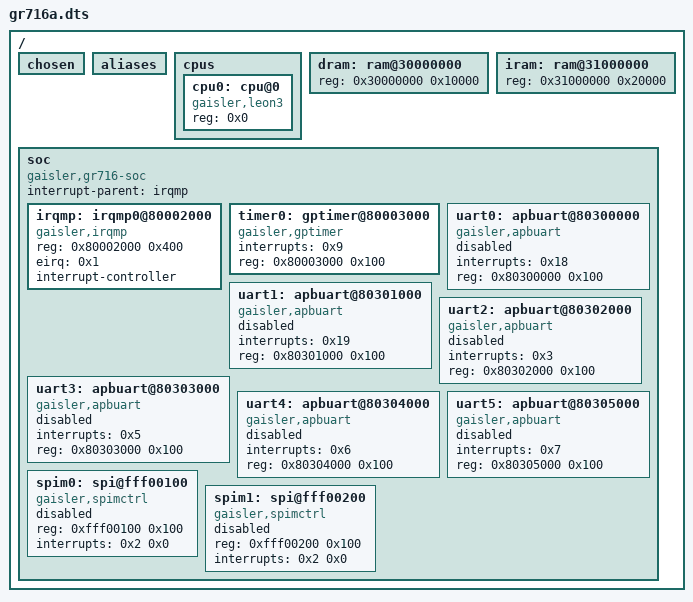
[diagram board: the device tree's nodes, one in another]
/dts-v1/;

/ {
	#address-cells = < 0x1 >;
	#size-cells = < 0x1 >;
	chosen {
	};
	aliases {
	};
	cpus {
		#address-cells = < 0x1 >;
		#size-cells = < 0x0 >;
		cpu0: cpu@0 {
			compatible = "gaisler,leon3";
			reg = < 0x0 >;
		};
	};
	dram: ram@30000000 {
		reg = < 0x30000000 0x10000 >;
	};
	iram: ram@31000000 {
		reg = < 0x31000000 0x20000 >;
	};
	soc {
		#address-cells = < 0x1 >;
		#size-cells = < 0x1 >;
		compatible = "gaisler,gr716-soc", "simple-bus";
		ranges;
		interrupt-parent = < &irqmp >;
		irqmp: irqmp0@80002000 {
			compatible = "gaisler,irqmp";
			reg = < 0x80002000 0x400 >;
			eirq = < 0x1 >;
			interrupt-controller;
			#interrupt-cells = < 0x1 >;
			phandle = < 0x1 >;
		};
		timer0: gptimer@80003000 {
			compatible = "gaisler,gptimer";
			interrupts = < 0x9 >;
			reg = < 0x80003000 0x100 >;
		};
		uart0: apbuart@80300000 {
			compatible = "gaisler,apbuart";
			interrupts = < 0x18 >;
			reg = < 0x80300000 0x100 >;
			status = "disabled";
		};
		uart1: apbuart@80301000 {
			compatible = "gaisler,apbuart";
			interrupts = < 0x19 >;
			reg = < 0x80301000 0x100 >;
			status = "disabled";
		};
		uart2: apbuart@80302000 {
			compatible = "gaisler,apbuart";
			interrupts = < 0x3 >;
			reg = < 0x80302000 0x100 >;
			status = "disabled";
		};
		uart3: apbuart@80303000 {
			compatible = "gaisler,apbuart";
			interrupts = < 0x5 >;
			reg = < 0x80303000 0x100 >;
			status = "disabled";
		};
		uart4: apbuart@80304000 {
			compatible = "gaisler,apbuart";
			interrupts = < 0x6 >;
			reg = < 0x80304000 0x100 >;
			status = "disabled";
		};
		uart5: apbuart@80305000 {
			compatible = "gaisler,apbuart";
			interrupts = < 0x7 >;
			reg = < 0x80305000 0x100 >;
			status = "disabled";
		};
		spim0: spi@fff00100 {
			compatible = "gaisler,spimctrl";
			reg = < 0xfff00100 0x100 >;
			interrupts = < 0x2 0x0 >;
			#address-cells = < 0x1 >;
			#size-cells = < 0x0 >;
			status = "disabled";
		};
		spim1: spi@fff00200 {
			compatible = "gaisler,spimctrl";
			reg = < 0xfff00200 0x100 >;
			interrupts = < 0x2 0x0 >;
			#address-cells = < 0x1 >;
			#size-cells = < 0x0 >;
			status = "disabled";
		};
	};
};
